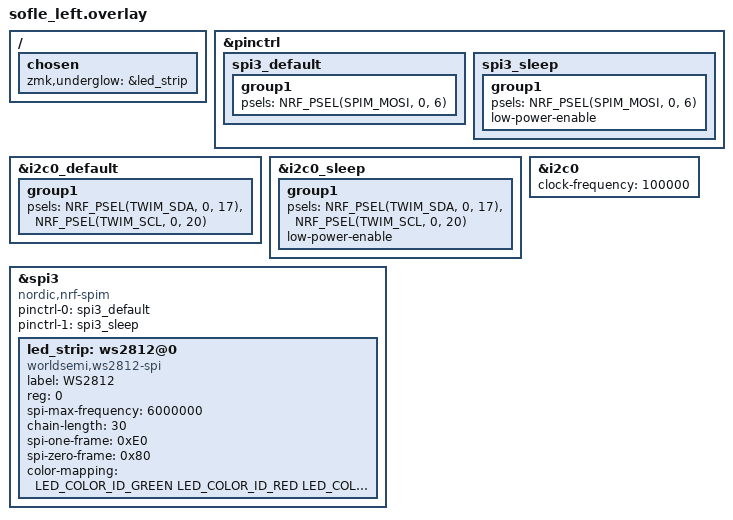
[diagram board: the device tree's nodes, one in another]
/*
 * Copyright (c) 2023 The ZMK Contributors
 * SPDX-License-Identifier: MIT
 *
 * Sofle Choc Wireless (left half) overlay for RGB underglow and OLED.
 * Pin assignments based on db-ok/SofleChocWireless reference project:
 *   https://github.com/db-ok/SofleChocWireless
 *   https://github.com/db-ok/zmk-config-soflechocwireless
 *
 * Pin mapping confirmed from hardware:
 *   RGB SPI : DIN = P0.06                 (NOT P0.08 as previously assumed)
 *   OLED I2C: SDA = P0.17, SCL = P0.20
 *
 * The built-in Sofle OLED node uses I2C0. Only its ProMicroNRF52840 pinctrl is
 * retained here explicitly to match this PCB.
 */

#include <dt-bindings/led/led.h>

&pinctrl {
    spi3_default: spi3_default {
        group1 {
            psels = <NRF_PSEL(SPIM_MOSI, 0, 6)>;
        };
    };

    spi3_sleep: spi3_sleep {
        group1 {
            psels = <NRF_PSEL(SPIM_MOSI, 0, 6)>;
            low-power-enable;
        };
    };

};

&i2c0_default {
    group1 {
        psels = <NRF_PSEL(TWIM_SDA, 0, 17)>, <NRF_PSEL(TWIM_SCL, 0, 20)>;
    };
};

&i2c0_sleep {
    group1 {
        psels = <NRF_PSEL(TWIM_SDA, 0, 17)>, <NRF_PSEL(TWIM_SCL, 0, 20)>;
        low-power-enable;
    };
};

&spi3 {
    compatible = "nordic,nrf-spim";
    status = "okay";

    pinctrl-0 = <&spi3_default>;
    pinctrl-1 = <&spi3_sleep>;
    pinctrl-names = "default", "sleep";

    led_strip: ws2812@0 {
        compatible = "worldsemi,ws2812-spi";
        label = "WS2812";

        /* SPI */
        reg = <0>;
        spi-max-frequency = <6000000>;

        /* WS2812 */
        chain-length = <30>; /* Single half: 30 WS2812 LEDs (underglow) */
        spi-one-frame = <0xE0>;
        spi-zero-frame = <0x80>;
        color-mapping = <LED_COLOR_ID_GREEN LED_COLOR_ID_RED LED_COLOR_ID_BLUE>;
    };
};

&i2c0 {
    status = "okay";
    clock-frequency = <100000>;
};

/ {
    chosen {
        zmk,underglow = &led_strip;
    };
};
